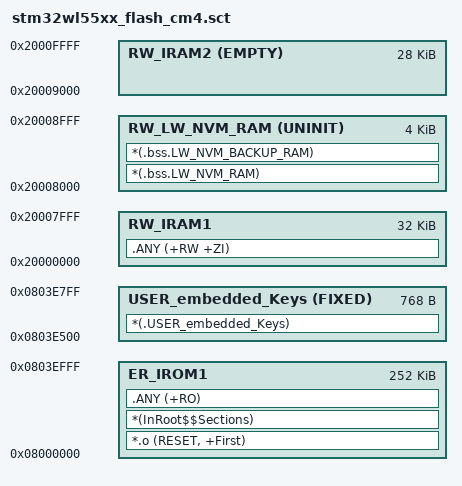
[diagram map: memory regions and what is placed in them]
; *************************************************************
; *** Scatter-Loading Description File generated by uVision ***
; *************************************************************

LR_IROM1 0x08000000 0x00040000  {    ; load region size_region
  ; FLASH
  ER_IROM1 0x08000000 0x0003F000  {  ; load address = execution address
   *.o (RESET, +First)
   *(InRoot$$Sections)
   .ANY (+RO)
  }

  ; NVM FLASH Data
  ; WARNING: Symbols not used. The NVMS address is defined in lora_app.c
  ; RW_LW_NVM_ROM 0x0803F000 0x00001000

  ; Non-backup SRAM1
  RW_IRAM1 0x20000000 0x00008000  {  ; RW data
   .ANY (+RW +ZI)
  }

  ; NVM RAM Data
  RW_LW_NVM_RAM 0x20008000 UNINIT 0x00001000  {  ;no init RW data
   *(.bss.LW_NVM_RAM)
   *(.bss.LW_NVM_BACKUP_RAM)
  }

  ; Backup SRAM2
  RW_IRAM2 0x20009000 EMPTY 0x00007000  {  ; to be modified accordingly to user project. Can be NoInit data for backup usage, RW, ZI region, etc...
  }
}

LR_IROM2 0x0803E500 0x00000300  {    ; load region size_region
  ;SE Embedded Keys
  USER_embedded_Keys 0x0803E500 FIXED 0x300 {
    *(.USER_embedded_Keys)
  }
}
